# STM32U575 register map
File version: 1.4
CPU: CM33 r0p1, little endian, MPU, FPU, 4 interrupt priority bits
Registers are 32-bit, read-write, reset 0x0 unless marked. A register's access mark holds for its fields unless they carry their own. Offsets are from the block's base; [hi:lo] are bit positions; {n}, {i} and the like mark numbered series; 'fields as' and 'values as' point back to an identical list.

## TIM1 (part 1 of 2) — Advanced-timers
Base 0x40012C00
Same registers: TIM8 0x40013400, SEC_TIM1 0x50012C00, SEC_TIM8 0x50013400
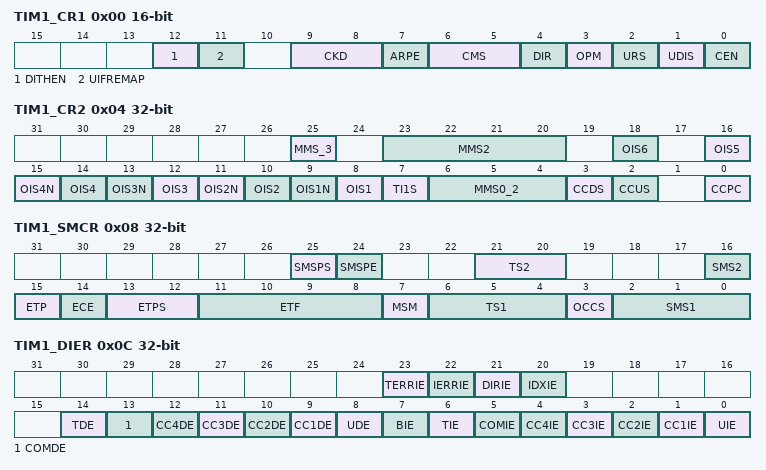
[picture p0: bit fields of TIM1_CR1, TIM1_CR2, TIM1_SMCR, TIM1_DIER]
0x00 TIM1_CR1 16-bit — TIM1 control register 1
  [12] DITHEN — Dithering enable Note: The DITHEN bit can only be modified when CEN bit is reset.
    0=Dithering disabled; 1=Dithering enabled
  [11] UIFREMAP — UIF status bit remapping
    0=No remapping. UIF status bit is not copied to TIMx_CNT register bit 31.; 1=Remapping enabled. UIF status bit is copied to TIMx_CNT register bit 31.
  [9:8] CKD — Clock division This bit-field indicates the division ratio between the timer clock (tim_ker_ck) frequency and the dead-time and sampling clock (tDTS)used by the dead-time generators and the digital filters (tim_etr_in, tim_tix),
    0=tDTS=ttim_ker_ck; 1=tDTS=2*ttim_ker_ck; 2=tDTS=4*ttim_ker_ck; 3=Reserved, do not program this value
  [7] ARPE — Auto-reload preload enable
    0=TIMx_ARR register is not buffered; 1=TIMx_ARR register is buffered
  [6:5] CMS — Center-aligned mode selection Note: It is not allowed to switch from edge-aligned mode to center-aligned mode as long as the counter is enabled (CEN=1)
    0=Edge-aligned mode. The counter counts up or down depending on the direction bit (DIR).; 1=Center-aligned mode 1. The counter counts up and down alternatively. Output compare interrupt flags of channels configured in output (CCxS=00 in TIMx_CCMRx register) are set only when the counter is counting down.; 2=Center-aligned mode 2. The counter counts up and down alternatively. Output compare interrupt flags of channels configured in output (CCxS=00 in TIMx_CCMRx register) are set only when the counter is counting up.; 3=Center-aligned mode 3. The counter counts up and down alternatively. Output compare interrupt flags of channels configured in output (CCxS=00 in TIMx_CCMRx register) are set both when the counter is counting up or down.
  [4] DIR — Direction Note: This bit is read only when the timer is configured in Center-aligned mode or Encoder mode.
    0=Counter used as upcounter; 1=Counter used as downcounter
  [3] OPM — One pulse mode
    0=Counter is not stopped at update event; 1=Counter stops counting at the next update event (clearing the bit CEN)
  [2] URS — Update request source This bit is set and cleared by software to select the UEV event sources. Counter overflow/underflow Setting the UG bit Update generation through the slave mode controller
    0=Any of the following events generate an update interrupt or DMA request if enabled. These events can be:; 1=Only counter overflow/underflow generates an update interrupt or DMA request if enabled
  [1] UDIS — Update disable This bit is set and cleared by software to enable/disable UEV event generation. Counter overflow/underflow Setting the UG bit Update generation through the slave mode controller Buffered registers are then loaded with their preload values.
    0=UEV enabled. The Update (UEV) event is generated by one of the following events:; 1=UEV disabled. The Update event is not generated, shadow registers keep their value (ARR, PSC, CCRx). However the counter and the prescaler are reinitialized if the UG bit is set or if a hardware reset is received from the slave mode controller.
  [0] CEN — Counter enable Note: External clock, gated mode and encoder mode can work only if the CEN bit has been previously set by software. However trigger mode can set the CEN bit automatically by hardware.
    0=Counter disabled; 1=Counter enabled
0x04 TIM1_CR2 — control register 2
  [25] MMS_3 — Master mode selection 2
  [23:20] MMS2 — Master mode selection 2
  [2n+6] OIS{n} (n=1..6) — Output Idle state {n}
  [15] OIS4N — Output Idle state 4 (OC5 output)
  [13] OIS3N — Output Idle state 3
  [11] OIS2N — Output Idle state 2
  [9] OIS1N — Output Idle state 1
  [7] TI1S — TI1 selection
  [6:4] MMS0_2 — Master mode selection
  [3] CCDS — Capture/compare DMA selection
  [2] CCUS — Capture/compare control update selection
  [0] CCPC — Capture/compare preloaded control
0x08 TIM1_SMCR — TIM1 slave mode control register
  [25] SMSPS — SMS preload source This bit selects whether the events that triggers the SMS[3:0] bitfield transfer from preload to active
    0=The transfer is triggered by the Timerâs Update event; 1=The transfer is triggered by the Index event
  [24] SMSPE — SMS preload enable This bit selects whether the SMS[3:0] bitfield is preloaded
    0=SMS[3:0]âbitfield is not preloadedâ; 1=SMS[3:0] preload is enabled
  [21:20] TS2 — Trigger selection - bit 4:3 Refer to TS[2:0] description - bits 6:4 null Trigger selection This bitfield is combined with TS[4:3] bits. This bit-field selects the trigger input to be used to synchronize the counter. others: Reserved See for more details on tim_itrx meaning for each Timer. Note: These bits must be changed only when they are not used (e.g. when SMS=000) to avoid wrong edge detections at the transition.
    {v}=Internal Trigger {v} (tim_itr{v}) (v=0..3); 4=tim_ti1 Edge Detector (tim_ti1f_ed); 5=Filtered Timer Input 1 (tim_ti1fp1); 6=Filtered Timer Input 2 (tim_ti2fp2); 7=External Trigger input (tim_etrf); 8=Internal Trigger 0 (tim_itr4); {v}=Internal Trigger 1 (tim_itr{v-4}) (v=9..14)
  [16] SMS2 — Slave mode selection When external signals are selected the active edge of the trigger signal (tim_trgi) is linked to the polarity selected on the external input (see Input Control register and Control Register description. Note: The gated mode must not be used if tim_ti1f_ed is selected as the trigger input (TS=00100). Indeed, tim_ti1f_ed outputs 1 pulse for each transition on TI1F, whereas the gated mode checks the level of the trigger signal. Note: The clock of the slave peripherals (timer, ADC, ...) receiving the tim_trgo or the tim_trgo2 signals must be enabled prior to receive events from the master timer, and the clock frequency (prescaler) must not be changed on-the-fly while triggers are received from the master timer.
    0=Slave mode disabled - if CEN = '1â then the prescaler is clocked directly by the internal clock; 1=Quadrature encoder mode 1, x2 mode- Counter counts up/down on tim_ti1fp1 edge depending on tim_ti2fp2 level; 2=Quadrature encoder mode 2, x2 mode - Counter counts up/down on tim_ti2fp2 edge depending on tim_ti1fp1 level; 3=Quadrature encoder mode 3, x4 mode - Counter counts up/down on both tim_ti1fp1 and tim_ti2fp2 edges depending on the level of the other input; 4=Reset Mode - Rising edge of the selected trigger input (tim_trgi) reinitializes the counter and generates an update of the registers; 5=Gated Mode - The counter clock is enabled when the trigger input (tim_trgi) is high. The counter stops (but is not reset) as soon as the trigger becomes low. Both start and stop of the counter are controlled.; 6=Trigger Mode - The counter starts at a rising edge of the trigger tim_trgi (but it is not reset). Only the start of the counter is controlled.; 7=External Clock Mode 1 - Rising edges of the selected trigger (tim_trgi) clock the counter; 8=Combined reset + trigger mode - Rising edge of the selected trigger input (tim_trgi) reinitializes the counter, generates an update of the registers and starts the counter; 9=Combined gated + reset mode - The counter clock is enabled when the trigger input (tim_trgi) is high. The counter stops and is reset) as soon as the trigger becomes low. Both start and stop of the counter are controlled.; 10=Encoder mode: Clock plus direction, x2 mode; 11=Encoder mode: Clock plus direction, x1 mode, tim_ti2fp2 edge sensitivity is set by CC2P; 12=Encoder mode: Directional Clock, x2 mode; 13=Encoder mode: Directional Clock, x1 mode, tim_ti1fp1 and tim_ti2fp2 edge sensitivity is set by CC1P and CC2P; 14=Quadrature encoder mode: x1 mode, counting on tim_ti1fp1 edges only, edge sensitivity is set by CC1P; 15=Quadrature encoder mode: x1 mode, counting on tim_ti2fp2 edges only, edge sensitivity is set by CC2P
  [15] ETP — External trigger polarity This bit selects whether tim_etr_in or tim_etr_in is used for trigger operations
    0=tim_etr_in is non-inverted, active at high level or rising edge; 1=tim_etr_in is inverted, active at low level or falling edge
  [14] ECE — External clock enable This bit enables External clock mode 2. Note: Setting the ECE bit has the same effect as selecting external clock mode 1 with tim_trgi connected to tim_etrf (SMS=111 and TS=00111). It is possible to simultaneously use external clock mode 2 with the following slave modes: reset mode, gated mode and trigger mode. Nevertheless, tim_trgi must not be connected to tim_etrf in this case (TS bits must not be 00111). If external clock mode 1 and external clock mode 2 are enabled at the same time, the external clock input is tim_etrf.
    0=External clock mode 2 disabled; 1=External clock mode 2 enabled. The counter is clocked by any active edge on the tim_etrf signal.
  [13:12] ETPS — External trigger prescaler External trigger signal tim_etrp frequency must be at most 1/4 of TIMxCLK frequency. A prescaler can be enabled to reduce tim_etrp frequency. It is useful when inputting fast external clocks on tim_etr_in.
    0=Prescaler OFF; 1=tim_etr_in frequency divided by 2; 2=tim_etr_in frequency divided by 4; 3=tim_etr_in frequency divided by 8
  [11:8] ETF — External trigger filter This bit-field then defines the frequency used to sample tim_etrp signal and the length of the digital filter applied to tim_etrp. The digital filter is made of an event counter in which N consecutive events are needed to validate a transition on the output:
    0=No filter, sampling is done at fDTS; 1=fSAMPLING=ftim_ker_ck, N=2; 2=fSAMPLING=ftim_ker_ck, N=4; 3=fSAMPLING=ftim_ker_ck, N=8; 4=fSAMPLING=fDTS/2, N=6; 5=fSAMPLING=fDTS/2, N=8; 6=fSAMPLING=fDTS/4, N=6; 7=fSAMPLING=fDTS/4, N=8; 8=fSAMPLING=fDTS/8, N=6; 9=fSAMPLING=fDTS/8, N=8; 10=fSAMPLING=fDTS/16, N=5; 11=fSAMPLING=fDTS/16, N=6; 12=fSAMPLING=fDTS/16, N=8; 13=fSAMPLING=fDTS/32, N=5; 14=fSAMPLING=fDTS/32, N=6; 15=fSAMPLING=fDTS/32, N=8
  [7] MSM — Master/slave mode
    0=No action; 1=The effect of an event on the trigger input (tim_trgi) is delayed to allow a perfect synchronization between the current timer and its slaves (through tim_trgo). It is useful if we want to synchronize several timers on a single external event.
  [6:4] TS1 — Trigger selection - bit 4:3 Refer to TS[2:0] description - bits 6:4 null Trigger selection This bitfield is combined with TS[4:3] bits. This bit-field selects the trigger input to be used to synchronize the counter. others: Reserved See for more details on tim_itrx meaning for each Timer. Note: These bits must be changed only when they are not used (e.g. when SMS=000) to avoid wrong edge detections at the transition.
    values as TS2
  [3] OCCS — OCREF clear selection This bit is used to select the OCREF clear source.
    0=tim_ocref_clr_int is connected to the tim_ocref_clr input; 1=tim_ocref_clr_int is connected to tim_etrf
  [2:0] SMS1 — Slave mode selection When external signals are selected the active edge of the trigger signal (tim_trgi) is linked to the polarity selected on the external input (see Input Control register and Control Register description. Note: The gated mode must not be used if tim_ti1f_ed is selected as the trigger input (TS=00100). Indeed, tim_ti1f_ed outputs 1 pulse for each transition on TI1F, whereas the gated mode checks the level of the trigger signal. Note: The clock of the slave peripherals (timer, ADC, ...) receiving the tim_trgo or the tim_trgo2 signals must be enabled prior to receive events from the master timer, and the clock frequency (prescaler) must not be changed on-the-fly while triggers are received from the master timer.
    values as SMS2
0x0C TIM1_DIER — TIM1 DMA/interrupt enable register
  [23] TERRIE — Transition error interrupt enable
    0=Transition error interrupt disabled; 1=Transition error interrupt enabled
  [22] IERRIE — Index error interrupt enable
    0=Index error interrupt disabled; 1=Index error interrupt enabled
  [21] DIRIE — Direction change interrupt enable
    0=Direction Change interrupt disabled; 1=Direction Change interrupt enabled
  [20] IDXIE — Index interrupt enable
    0=Index interrupt disabled; 1=Index Change interrupt enabled
  [14] TDE — Trigger DMA request enable
    0=Trigger DMA request disabled; 1=Trigger DMA request enabled
  [13] COMDE — COM DMA request enable
    0=COM DMA request disabled; 1=COM DMA request enabled
  [n+8] CC{n}DE (n=1..4) — Capture/compare {n} DMA request enable
    0=CC{n} DMA request disabled; 1=CC{n} DMA request enabled
  [8] UDE — Update DMA request enable
    0=Update DMA request disabled; 1=Update DMA request enabled
  [7] BIE — Break interrupt enable
    0=Break interrupt disabled; 1=Break interrupt enabled
  [6] TIE — Trigger interrupt enable
    0=Trigger interrupt disabled; 1=Trigger interrupt enabled
  [5] COMIE — COM interrupt enable
    0=COM interrupt disabled; 1=COM interrupt enabled
  [n] CC{n}IE (n=1..4) — Capture/compare {n} interrupt enable
    0=CC{n} interrupt disabled; 1=CC{n} interrupt enabled
  [0] UIE — Update interrupt enable
    0=Update interrupt disabled; 1=Update interrupt enabled
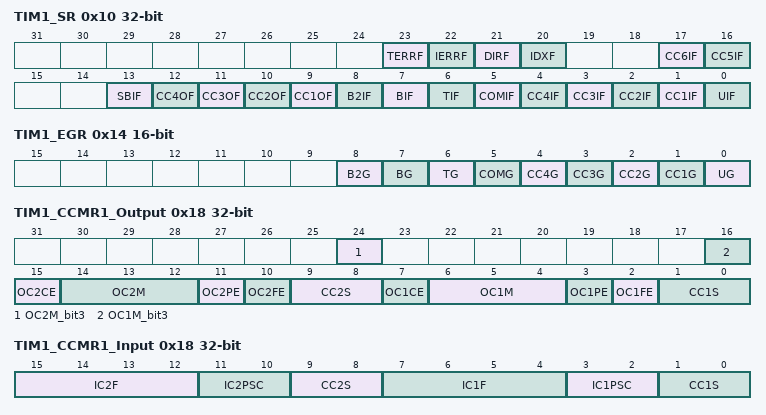
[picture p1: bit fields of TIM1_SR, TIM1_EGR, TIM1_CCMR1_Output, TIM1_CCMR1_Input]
0x10 TIM1_SR — TIM1 status register
  [23] TERRF — Transition error interrupt flag This flag is set by hardware when a transition error is detected in encoder mode. It is cleared by software by writing it to '0â.
    0=No encoder transition error has been detected; 1=An encoder transition error has been detected
  [22] IERRF — Index error interrupt flag This flag is set by hardware when an index error is detected. It is cleared by software by writing it to '0â.
    0=No index error has been detected; 1=An index error has been detected
  [21] DIRF — Direction change interrupt flag This flag is set by hardware when the direction changes in encoder mode (DIR bit value in TIMx_CR is changing). It is cleared by software by writing it to '0â.
    0=No direction change; 1=Direction change
  [20] IDXF — Index interrupt flag This flag is set by hardware when an index event is detected. It is cleared by software by writing it to '0â.
    0=No index event occurred; 1=An index event has occurred
  [17] CC6IF — Compare 6 interrupt flag Refer to CC1IF description Note: Channel 6 can only be configured as output.
  [16] CC5IF — Compare 5 interrupt flag Refer to CC1IF description Note: Channel 5 can only be configured as output.
  [13] SBIF — System break interrupt flag This flag is set by hardware as soon as the system break input goes active. It can be cleared by software if the system break input is not active. This flag must be reset to re-start PWM operation.
    0=No break event occurred; 1=An active level has been detected on the system break input. An interrupt is generated if BIE=1 in the TIMx_DIER register.
  [12] CC4OF — Capture/compare 4 overcapture flag Refer to CC1OF description
  [11] CC3OF — Capture/compare 3 overcapture flag Refer to CC1OF description
  [10] CC2OF — Capture/compare 2 overcapture flag Refer to CC1OF description
  [9] CC1OF — Capture/compare 1 overcapture flag This flag is set by hardware only when the corresponding channel is configured in input capture mode. It is cleared by software by writing it to '0â.
    0=No overcapture has been detected; 1=The counter value has been captured in TIMx_CCR1 register while CC1IF flag was already set
  [8] B2IF — Break 2 interrupt flag This flag is set by hardware as soon as the break 2 input goes active. It can be cleared by software if the break 2 input is not active.
    0=No break event occurred; 1=An active level has been detected on the break 2 input. An interrupt is generated if BIE=1 in the TIMx_DIER register.
  [7] BIF — Break interrupt flag This flag is set by hardware as soon as the break input goes active. It can be cleared by software if the break input is not active.
    0=No break event occurred; 1=An active level has been detected on the break input. An interrupt is generated if BIE=1 in the TIMx_DIER register.
  [6] TIF — Trigger interrupt flag This flag is set by hardware on the TRG trigger event (active edge detected on tim_trgi input when the slave mode controller is enabled in all modes but gated mode. It is set when the counter starts or stops when gated mode is selected. It is cleared by software.
    0=No trigger event occurred; 1=Trigger interrupt pending
  [5] COMIF — COM interrupt flag This flag is set by hardware on COM event (when capture/compare Control bits - CCxE, CCxNE, OCxM - have been updated). It is cleared by software.
    0=No COM event occurred; 1=COM interrupt pending
  [4] CC4IF — Capture/compare 4 interrupt flag Refer to CC1IF description
  [3] CC3IF — Capture/compare 3 interrupt flag Refer to CC1IF description
  [2] CC2IF — Capture/compare 2 interrupt flag Refer to CC1IF description
  [1] CC1IF — Capture/compare 1 interrupt flag This flag is set by hardware. It is cleared by software (input capture or output compare mode) or by reading the TIMx_CCR1 register (input capture mode only). If channel CC1 is configured as output: this flag is set when the content of the counter TIMx_CNT matches the content of the TIMx_CCR1 register. When the content of TIMx_CCR1 is greater than the content of TIMx_ARR, the CC1IF bit goes high on the counter overflow (in up-counting and up/down-counting modes) or underflow (in downcounting mode). There are 3 possible options for flag setting in center-aligned mode, refer to the CMS bits in the TIMx_CR1 register for the full description. If channel CC1 is configured as input: this bit is set when counter value has been captured in TIMx_CCR1 register (an edge has been detected on IC1, as per the edge sensitivity defined with the CC1P and CC1NP bits setting, in TIMx_CCER).
    0=No compare match / No input capture occurred; 1=A compare match or an input capture occurred
  [0] UIF — Update interrupt flag This bit is set by hardware on an update event. It is cleared by software. At overflow or underflow regarding the repetition counter value (update if repetition counter = 0) and if the UDIS=0 in the TIMx_CR1 register. When CNT is reinitialized by software using the UG bit in TIMx_EGR register, if URS=0 and UDIS=0 in the TIMx_CR1 register. When CNT is reinitialized by a trigger event (refer to control register (TIMx_SMCR)(x = 1, 8)), if URS=0 and UDIS=0 in the TIMx_CR1 register.
    0=No update occurred; 1=Update interrupt pending. This bit is set by hardware when the registers are updated:
0x14 TIM1_EGR 16-bit wo — TIM1 event generation register
  [8] B2G — Break 2 generation This bit is set by software in order to generate an event, it is automatically cleared by hardware.
    0=No action; 1=A break 2 event is generated. MOE bit is cleared and B2IF flag is set. Related interrupt can occur if enabled.
  [7] BG — Break generation This bit is set by software in order to generate an event, it is automatically cleared by hardware.
    0=No action; 1=A break event is generated. MOE bit is cleared and BIF flag is set. Related interrupt or DMA transfer can occur if enabled.
  [6] TG — Trigger generation This bit is set by software in order to generate an event, it is automatically cleared by hardware.
    0=No action; 1=The TIF flag is set in TIMx_SR register. Related interrupt or DMA transfer can occur if enabled.
  [5] COMG — Capture/compare control update generation This bit can be set by software, it is automatically cleared by hardware Note: This bit acts only on channels having a complementary output.
    0=No action; 1=When CCPC bit is set, it allows to update CCxE, CCxNE and OCxM bits
  [4] CC4G — Capture/compare 4 generation Refer to CC1G description
  [3] CC3G — Capture/compare 3 generation Refer to CC1G description
  [2] CC2G — Capture/compare 2 generation Refer to CC1G description
  [1] CC1G — Capture/compare 1 generation This bit is set by software in order to generate an event, it is automatically cleared by hardware. If channel CC1 is configured as output: CC1IF flag is set, Corresponding interrupt or DMA request is sent if enabled. If channel CC1 is configured as input: The current value of the counter is captured in TIMx_CCR1 register. The CC1IF flag is set, the corresponding interrupt or DMA request is sent if enabled. The CC1OF flag is set if the CC1IF flag was already high.
    0=No action; 1=A capture/compare event is generated on channel 1:
  [0] UG — Update generation This bit can be set by software, it is automatically cleared by hardware.
    0=No action; 1=Reinitialize the counter and generates an update of the registers. Note that the prescaler counter is cleared too (anyway the prescaler ratio is not affected). The counter is cleared if the center-aligned mode is selected or if DIR=0 (upcounting), else it takes the auto-reload value (TIMx_ARR) if DIR=1 (downcounting).
0x18 TIM1_CCMR1_Output — capture/compare mode register 1 (output mode)
  [24] OC2M_bit3 — Output Compare 2 mode - bit 3
  [16] OC1M_bit3 — Output Compare 1 mode - bit 3
  [15] OC2CE — Output Compare 2 clear enable
  [14:12] OC2M — Output Compare 2 mode
  [11] OC2PE — Output Compare 2 preload enable
  [10] OC2FE — Output Compare 2 fast enable
  [9:8] CC2S — Capture/Compare 2 selection
  [7] OC1CE — Output Compare 1 clear enable
  [6:4] OC1M — Output Compare 1 mode
  [3] OC1PE — Output Compare 1 preload enable
  [2] OC1FE — Output Compare 1 fast enable
  [1:0] CC1S — Capture/Compare 1 selection
0x18 TIM1_CCMR1_Input (alternate view of TIM1_CCMR1_Output) — TIM1 capture/compare mode register 1 [alternate]
  [15:12] IC2F — Input capture 2 filter
  [11:10] IC2PSC — Input capture 2 prescaler
  [9:8] CC2S — Capture/compare 2 selection This bit-field defines the direction of the channel (input/output) as well as the used input. Note: CC2S bits are writable only when the channel is OFF (CC2E = '0â in TIMx_CCER).
    0=CC2 channel is configured as output; 1=CC2 channel is configured as input, tim_ic2 is mapped on tim_ti2; 2=CC2 channel is configured as input, tim_ic2 is mapped on tim_ti1; 3=CC2 channel is configured as input, tim_ic2 is mapped on tim_trc. This mode is working only if an internal trigger input is selected through TS bit (TIMx_SMCR register)
  [7:4] IC1F — Input capture 1 filter This bit-field defines the frequency used to sample tim_ti1 input and the length of the digital filter applied to tim_ti1. The digital filter is made of an event counter in which N consecutive events are needed to validate a transition on the output:
    values as TIM1_SMCR.ETF
  [3:2] IC1PSC — Input capture 1 prescaler This bit-field defines the ratio of the prescaler acting on CC1 input (tim_ic1). The prescaler is reset as soon as CC1E=â0â (TIMx_CCER register).
    0=no prescaler, capture is done each time an edge is detected on the capture input; 1=capture is done once every 2 events; 2=capture is done once every 4 events; 3=capture is done once every 8 events
  [1:0] CC1S — Capture/compare 1 Selection This bit-field defines the direction of the channel (input/output) as well as the used input. Note: CC1S bits are writable only when the channel is OFF (CC1E = '0â in TIMx_CCER).
    0=CC1 channel is configured as output; 1=CC1 channel is configured as input, tim_ic1 is mapped on tim_ti1; 2=CC1 channel is configured as input, tim_ic1 is mapped on tim_ti2; 3=CC1 channel is configured as input, tim_ic1 is mapped on tim_trc. This mode is working only if an internal trigger input is selected through TS bit (TIMx_SMCR register)
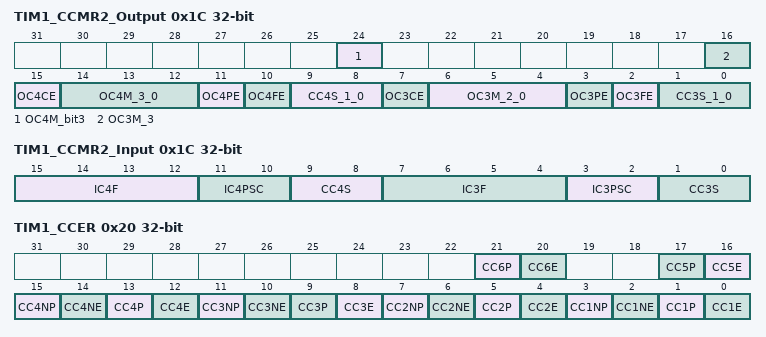
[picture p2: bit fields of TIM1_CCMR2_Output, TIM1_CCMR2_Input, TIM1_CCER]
0x1C TIM1_CCMR2_Output — capture/compare mode register 2 (output mode)
  [24] OC4M_bit3 — Output Compare 4 mode - bit 3
  [16] OC3M_3 — Output compare 3 mode
  [15] OC4CE — Output compare 4 clear enable
  [14:12] OC4M_3_0 — Output compare 4 mode
  [11] OC4PE — Output compare 4 preload enable
  [10] OC4FE — Output compare 4 fast enable
  [9:8] CC4S_1_0 — Capture/Compare 4 selection
  [7] OC3CE — Output compare 3 clear enable
  [6:4] OC3M_2_0 — Output compare 3 mode
  [3] OC3PE — Output compare 3 preload enable
  [2] OC3FE — Output compare 3 fast enable
  [1:0] CC3S_1_0 — Capture/Compare 3 selection
0x1C TIM1_CCMR2_Input (alternate view of TIM1_CCMR2_Output) — TIM1 capture/compare mode register 2 [alternate]
  [15:12] IC4F — Input capture 4 filter
  [11:10] IC4PSC — Input capture 4 prescaler
  [9:8] CC4S — Capture/compare 4 selection This bit-field defines the direction of the channel (input/output) as well as the used input. Note: CC4S bits are writable only when the channel is OFF (CC4E = '0â in TIMx_CCER).
    0=CC4 channel is configured as output; 1=CC4 channel is configured as input, tim_ic4 is mapped on tim_ti4; 2=CC4 channel is configured as input, tim_ic4 is mapped on tim_ti3; 3=CC4 channel is configured as input, tim_ic4 is mapped on tim_trc. This mode is working only if an internal trigger input is selected through TS bit (TIMx_SMCR register)
  [7:4] IC3F — Input capture 3 filter
  [3:2] IC3PSC — Input capture 3 prescaler
  [1:0] CC3S — Capture/compare 3 selection This bit-field defines the direction of the channel (input/output) as well as the used input. Note: CC3S bits are writable only when the channel is OFF (CC3E = '0â in TIMx_CCER).
    0=CC3 channel is configured as output; 1=CC3 channel is configured as input, tim_ic3 is mapped on tim_ti3; 2=CC3 channel is configured as input, tim_ic3 is mapped on tim_ti4; 3=CC3 channel is configured as input, tim_ic3 is mapped on tim_trc. This mode is working only if an internal trigger input is selected through TS bit (TIMx_SMCR register)
0x20 TIM1_CCER — TIM1 capture/compare enable register
  [4n-3] CC{n}P (n=2..6) — Capture/compare {n} output polarity Refer to CC1P description
  [4n-4] CC{n}E (n=2..6) — Capture/compare {n} output enable Refer to CC1E description
  [15] CC4NP — Capture/compare 4 complementary output polarity Refer to CC1NP description
  [14] CC4NE — Capture/compare 4 complementary output enable Refer to CC1NE description
  [11] CC3NP — Capture/compare 3 complementary output polarity Refer to CC1NP description
  [10] CC3NE — Capture/compare 3 complementary output enable Refer to CC1NE description
  [7] CC2NP — Capture/compare 2 complementary output polarity Refer to CC1NP description
  [6] CC2NE — Capture/compare 2 complementary output enable Refer to CC1NE description
  [3] CC1NP — Capture/compare 1 complementary output polarity CC1 channel configured as output: CC1 channel configured as input: This bit is used in conjunction with CC1P to define the polarity of tim_ti1fp1 and tim_ti2fp1. Refer to CC1P description. Note: This bit is not writable as soon as LOCK level 2 or 3 has been programmed (LOCK bits in TIMx_BDTR register) and CC1S=â00â (channel configured as output). Note: On channels having a complementary output, this bit is preloaded. If the CCPC bit is set in the TIMx_CR2 register then the CC1NP active bit takes the new value from the preloaded bit only when a Commutation event is generated.
    0=tim_oc1n active high; 1=tim_oc1n active low
  [2] CC1NE — Capture/compare 1 complementary output enable Note: On channels having a complementary output, this bit is preloaded. If the CCPC bit is set in the TIMx_CR2 register then the CC1NE active bit takes the new value from the preloaded bit only when a Commutation event is generated.
    0=Off - tim_oc1n is not active. tim_oc1n level is then function of MOE, OSSI, OSSR, OIS1, OIS1N and CC1E bits.; 1=On - tim_oc1n signal is output on the corresponding output pin depending on MOE, OSSI, OSSR, OIS1, OIS1N and CC1E bits
  [1] CC1P — Capture/compare 1 output polarity When CC1 channel is configured as input, both CC1NP/CC1P bits select the active polarity of TI1FP1 and TI2FP1 for trigger or capture operations. CC1NP=0, CC1P=0: non-inverted/rising edge. The circuit is sensitive to TIxFP1 rising edge (capture or trigger operations in reset, external clock or trigger mode), TIxFP1 is not inverted (trigger operation in gated mode or encoder mode). CC1NP=0, CC1P=1: inverted/falling edge. The circuit is sensitive to TIxFP1 falling edge (capture or trigger operations in reset, external clock or trigger mode), TIxFP1 is inverted (trigger operation in gated mode or encoder mode). CC1NP=1, CC1P=1: non-inverted/both edges/ The circuit is sensitive to both TIxFP1 rising and falling edges (capture or trigger operations in reset, external clock or trigger mode), TIxFP1is not inverted (trigger operation in gated mode). This configuration must not be used in encoder mode. CC1NP=1, CC1P=0: the configuration is reserved, it must not be used. Note: This bit is not writable as soon as LOCK level 2 or 3 has been programmed (LOCK bits in TIMx_BDTR register). Note: On channels having a complementary output, this bit is preloaded. If the CCPC bit is set in the TIMx_CR2 register then the CC1P active bit takes the new value from the preloaded bit only when a Commutation event is generated.
    0=OC1 active high (output mode) / Edge sensitivity selection (input mode, see below); 1=OC1 active low (output mode) / Edge sensitivity selection (input mode, see below)
  [0] CC1E — Capture/compare 1 output enable When CC1 channel is configured as output, the OC1 level depends on MOE, OSSI, OSSR, OIS1, OIS1N and CC1NE bits, regardless of the CC1E bits state. Refer to for details. Note: On channels having a complementary output, this bit is preloaded. If the CCPC bit is set in the TIMx_CR2 register then the CC1E active bit takes the new value from the preloaded bit only when a Commutation event is generated.
    0=Capture mode disabled / OC1 is not active (see below); 1=Capture mode enabled / OC1 signal is output on the corresponding output pin
